# nrf7140_application register map
Vendor: Nordic Semiconductor; Series: nRF71; File version: 1
CPU: CM33 r0p4, little endian, MPU, FPU, 3 interrupt priority bits, 480 interrupts, 8 SAU regions
Registers are 32-bit, read-write, reset 0x0 unless marked. A register's access mark holds for its fields unless they carry their own. Offsets are from the block's base; [hi:lo] are bit positions; lines under a group give offsets from that group; {n}, {i} and the like mark numbered series; 'fields as' and 'values as' point back to an identical list.

## GLOBAL_GSI_NS (part 2 of 3) — GSI
Base 0x49008000
0x1000 DSI group — Unspecified
  0x00 VERSION reset 0x30313531 — Contains the version of the DSI host controller.
    [31:0] VERSION ro — This field indicates the version of the DSI.
  0x04 PWRUP — Controls the power up of the controller.
    [0] SHUTDOWNZ — This bit configures the controller either to power up or to reset.
      0=RESET (Reset the controller); 1=POWERUP (Power up the controller)
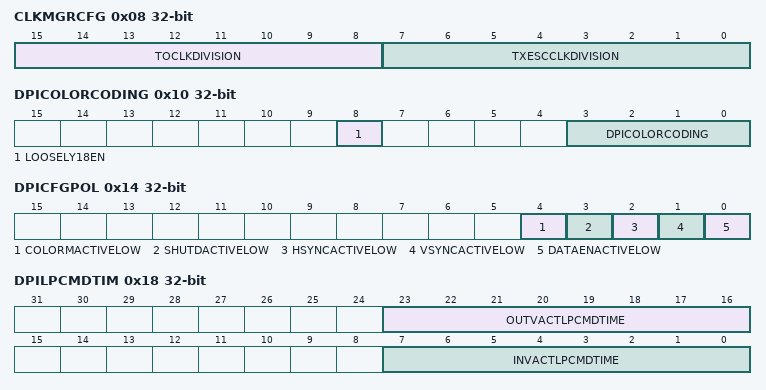
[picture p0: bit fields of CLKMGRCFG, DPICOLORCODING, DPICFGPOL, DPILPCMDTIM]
  0x08 CLKMGRCFG — Configures the factor for internal dividers to divide lanebyteclk for timeout purposes.
    [15:8] TOCLKDIVISION — This field indicates the division factor for the Time Out clock used as the timing unit in the configuration of high-speed to low-power and low-power to high-speed transition error.
    [7:0] TXESCCLKDIVISION — This field indicates the division factor for the TX Escape clock source (lanebyteclk). The values 0 and 1 stop the TX_ESC clock generation.
  0x0C DPIVCID — Configures the Virtual Channel ID for DPI traffic.
    [1:0] DPIVCID — This field configures the DPI virtual channel id that is indexed to the Video mode packets.
  0x10 DPICOLORCODING — Configures DPI color coding.
    [8] LOOSELY18EN — When set to 1, this bit activates loosely packed variant to 18-bit configurations.
    [3:0] DPICOLORCODING — This field configures the DPI color for Video Mode/eDPI Command Mode coding as follows:
      0=CC00 (16-bit configuration 1); 1=CC01 (16-bit configuration 2); 2=CC02 (16-bit configuration 3); 3=CC03 (18-bit configuration 1); 4=CC04 (18-bit configuration 2); 5=CC05 (24-bit); 6=CC06 (20-bit YCbCr 4:2:2 loosely packed / Reserved for eDPI Command Mode); 7=CC07 (24-bit YCbCr 4:2:2 / Reserved for eDPI Command Mode); 8=CC08 (16-bit YCbCr 4:2:2 / Reserved for eDPI Command Mode); 9=CC09 (30-bit - DSC_ENC 10bit / Reserved for eDPI Command Mode); 10=CC10 (36-bit / Reserved for eDPI Command Mode); 11=CC11 (12-bit YCbCr 4:2:0 / Reserved for eDPI Command Mode); 12=CC12 (DSC24 compressed Data); 13=CC13 (Unspecified); 14=CC14 (Unspecified); 15=CC15 (Unspecified)
  0x14 DPICFGPOL — Configures the polarity of DPI signals.
    [4] COLORMACTIVELOW — When set to 1, this bit configures the color mode pin (dpicolorm) as active low.
    [3] SHUTDACTIVELOW — When set to 1, this bit configures the shutdown pin (dpishutdn) as active low.
    [2] HSYNCACTIVELOW — When set to 1, this bit configures the horizontal synchronism pin (dpihsync) as active low.
    [1] VSYNCACTIVELOW — When set to 1, this bit configures the vertical synchronism pin (dpivsync) as active low.
    [0] DATAENACTIVELOW — When set to 1, this bit configures the data enable pin (dpidataen) as active low.
  0x18 DPILPCMDTIM — Configures the timing for low-power commands sent while in video mode.
    [23:16] OUTVACTLPCMDTIME — This field is used for the transmission of commands in low-power mode. It defines the size, in bytes, of the largest packet that can fit in a line during the VSA, VBP, and VFP regions.
    [7:0] INVACTLPCMDTIME — This field is used for the transmission of commands in low-power mode. It defines the size, in bytes, of the largest packet that can fit in a line during the VACT region.
  0x1C DBIVCID — Configures Virtual Channel ID for DBI traffic.
    [1:0] DBIVCID — This field configures the virtual channel id that is indexed to the DCS packets from DBI.
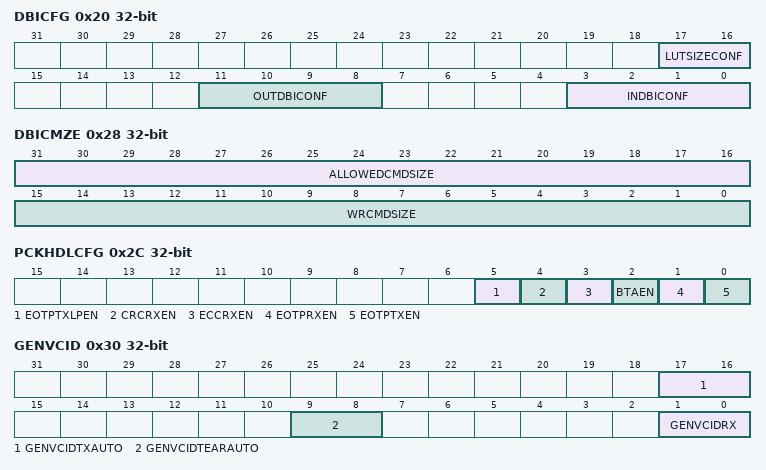
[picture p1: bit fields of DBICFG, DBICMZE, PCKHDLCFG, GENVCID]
  0x20 DBICFG — Configures the bit width of pixels for DBI.
    [17:16] LUTSIZECONF — This field configures the size used to transport the Write Lut commands as follows:
      0=LUTSIZE0 (16-bit color display); 1=LUTSIZE1 (18-bit color display); 2=LUTSIZE2 (24-bit color display); 3=LUTSIZE3 (32-bit color display)
    [11:8] OUTDBICONF — This field configures the DBI output pixel data as follows:
      0=PIXELDATA0 (8-bit 8 bpp); 1=PIXELDATA1 (8-bit 12 bpp); 2=PIXELDATA2 (8-bit 16 bpp); 3=PIXELDATA3 (8-bit 18 bpp); 4=PIXELDATA4 (8-bit 24 bpp); 5=PIXELDATA5 (9-bit 18 bpp); 6=PIXELDATA6 (16-bit 8 bpp); 7=PIXELDATA7 (16-bit 12 bpp); 8=PIXELDATA8 (16-bit 16 bpp); 9=PIXELDATA9 (16-bit 18 bpp, option 1); 10=PIXELDATA10 (16-bit 18 bpp, option 2); 11=PIXELDATA11 (16-bit 24 bpp, option 1); 12=PIXELDATA12 (16-bit 24 bpp, option 2)
    [3:0] INDBICONF — This field configures the DBI input pixel data as follows:
      values as OUTDBICONF
  0x24 DBIPARTITIONINGEN — Configures whether DSI is to partition DBI traffic automatically.
    [0] PARTITIONINGEN — When set to 1, this bit enables the use of write_memory_continue input commands (system needs to ensure correct partitioning of Long Write commands). When not set, partitioning is automatically performed in the DSI.
  0x28 DBICMZE — Configures the command size and the size for automatic partitioning of DBI packets.
    [31:16] ALLOWEDCMDSIZE — This field configures the maximum allowed size for a DCS write memory command. This field is used to partition a write memory command into one write_memory_start and a variable number of write_memory_continue commands. It is only used if the partitioning_en bit of the DBI_CFG register is disabled. The size of the DSI packet payload is the actual payload size minus 1, because the DCS command is in the DSI packet payload.
    [15:0] WRCMDSIZE — This field configures the size of the DCS write memory commands. The size of DSI packet payload is the actual payload size minus 1, because the DCS command is in the DSI packet payload.
  0x2C PCKHDLCFG — Configures how EoTp, BTA, CRC and ECC are to be used, to meet peripherals characteristics
    [5] EOTPTXLPEN — When set to 1, this bit enables the EoTp transmission in low-power.
    [4] CRCRXEN — When set to 1, this bit enables the CRC reception and error reporting.
    [3] ECCRXEN — When set to 1, this bit enables the ECC reception, error correction, and reporting.
    [2] BTAEN — When set to 1, this bit enables the Bus Turn-Around (BTA) request.
    [1] EOTPRXEN — When set to 1, this bit enables the EoTp reception.
    [0] EOTPTXEN — When set to 1, this bit enables the EoTp transmission in high-speed.
  0x30 GENVCID — Configures the Virtual Channel ID of READ responses to store and return to Generic interface.
    [17:16] GENVCIDTXAUTO — This field indicates the Generic interface virtual channel identification where generic packet is automatically generated & transmitted.
    [9:8] GENVCIDTEARAUTO — This field indicates the virtual channel identification for tear effect by hardware
    [1:0] GENVCIDRX — This field indicates the Generic interface read-back virtual channel identification.
  0x34 MODECFG reset 0x1 — Configures the mode of operation between Video or Command Mode. (Commands can still be sent while in video mode.)
    [0] CMDVIDEOMODE — This bit configures the operation mode:
      0=VIDMODE (video mode); 1=CMDMODE (command mode)
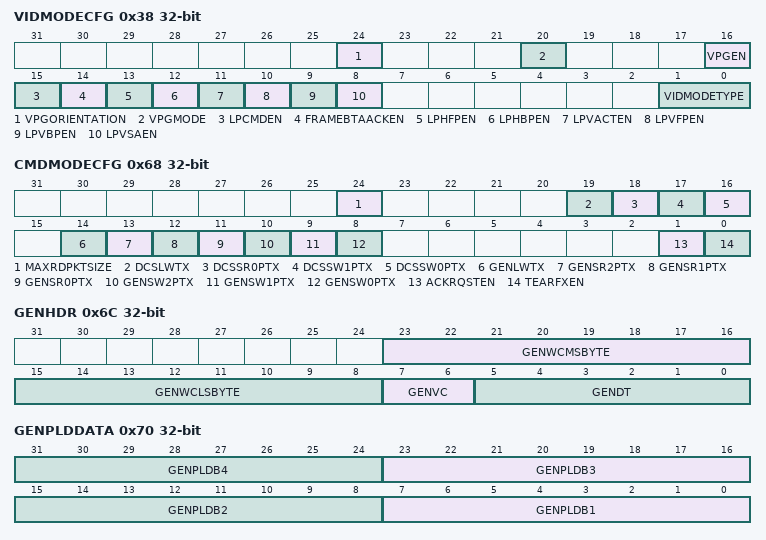
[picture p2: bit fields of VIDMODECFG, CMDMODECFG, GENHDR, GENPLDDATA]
  0x38 VIDMODECFG — Configures several aspects of Video mode operation, the transmission mode, switching to low-power in the middle of a frame, enabling acknowledge and whether to send commands in low-power.
    [24] VPGORIENTATION — This field indicates the color bar orientation as follows:
      0=VPGORENT0 (Vertical mode); 1=VPGORENT1 (Horizontal mode)
    [20] VPGMODE — This field is to select the pattern:
      0=COLORBAR (horizontal or vertical); 1=BERPATTERN (vertical only)
    [16] VPGEN — When set to 1, this bit enables the video mode pattern generator.
    [15] LPCMDEN — When set to 1, this bit enables the command transmission only in low-power mode.
    [14] FRAMEBTAACKEN — When set to 1, this bit enables the request for an acknowledge response at the end of a frame.
    [13] LPHFPEN — When set to 1, this bit enables the return to low-power inside the HFP period when timing allows.
    [12] LPHBPEN — When set to 1, this bit enables the return to low-power inside the HBP period when timing allows.
    [11] LPVACTEN — When set to 1, this bit enables the return to low-power inside the VACT period when timing allows.
    [10] LPVFPEN — When set to 1, this bit enables the return to low-power inside the VFP period when timing allows.
    [9] LPVBPEN — When set to 1, this bit enables the return to low-power inside the VBP period when timing allows.
    [8] LPVSAEN — When set to 1, this bit enables the return to low-power inside the VSA period when timing allows.
    [1:0] VIDMODETYPE — This field indicates the video mode transmission type as follows:
      0=VIDMODE0 (Non-burst with sync pulses); 1=VIDMODE1 (Non-burst with sync events); 2=VIDMODE2 (Burst mode); 3=VIDMODE3 (Burst mode)
  0x3C VIDPKTSIZE — Configures the video packet size.
    [13:0] VIDPKTSIZE — This field configures the number of pixels in a single video packet.
  0x40 VIDNUMCHUNKS — Configures the number of chunks to use. The data in each chunk has the size provided by VID_PKT_SIZE.
    [12:0] VIDNUMCHUNKS — This register configures the number of chunks to be transmitted during a Line period (a chunk is pair made of a video packet and a null packet). If set to 0 or 1, video line is still transmitted in a single packet. If set to 1 that packet is part of a chunk, meaning that a null packet follows it (if vid_null_size>0). Otherwise, multiple chunks are used to transmit each video line.
  0x44 VIDNULLSIZE — Configures the size of null packets.
    [12:0] VIDNULLSIZE — This register configures the number of bytes inside a null packet. Setting to 0 disables null packets.
  0x48 VIDHSATIME — Configures the video HSA time.
    [11:0] VIDHSATIME — This field configures the Horizontal Synchronism Active period in lane byte clock cycles.
  0x4C VIDHBPTIME — Configures the video HBP time.
    [11:0] VIDHBPTIME — This field configures the Horizontal Back Porch period in lane byte clock cycles.
  0x50 VIDHLINETIME — Configures the overall time for each video line.
    [14:0] VIDHLINETIME — This field configures the size of the total line time (HSA+HBP+HACT+HFP) counted in lane byte clock cycles.
  0x54 VIDVSALINES — Configures the VSA period.
    [9:0] VSALINES — This field configures the Vertical Synchronism Active period measured in number of horizontal lines.
  0x58 VIDVBPLINES — Configures the VBP period.
    [9:0] VBPLINES — This field configures the Vertical Back Porch period measured in number of horizontal lines.
  0x5C VIDVFPLINES — Configures the VFP period.
    [9:0] VFPLINES — This field configures the Vertical Front Porch period measured in number of horizontal lines.
  0x60 VIDVACTIVELINES — Configures the vertical resolution of video.
    [13:0] VACTIVELINES — This field configures the Vertical Active period measured in number of horizontal lines.
  0x68 CMDMODECFG — Configures several aspect of command mode operation, tearing effect, acknowledge for each packet and the speed mode to transmit each Data Type related to commands.
    [24] MAXRDPKTSIZE — This bit configures the maximum read packet size command transmission type:
      0=HIGHSPEED (Transition type is high-speed); 1=LOWPOWER (Transition type is low-power)
    [19] DCSLWTX — This bit configures the DCS long write packet command transmission type:
      values as MAXRDPKTSIZE
    [18] DCSSR0PTX — This bit configures the DCS short read packet with zero parameter command transmission type:
      values as MAXRDPKTSIZE
    [17] DCSSW1PTX — This bit configures the DCS short write packet with one parameter command transmission type:
      values as MAXRDPKTSIZE
    [16] DCSSW0PTX — This bit configures the DCS short write packet with zero parameter command transmission type:
      values as MAXRDPKTSIZE
    [14] GENLWTX — This bit configures the Generic long write packet command transmission type:
      values as MAXRDPKTSIZE
    [13] GENSR2PTX — This bit configures the Generic short read packet with two parameters command transmission type:
      values as MAXRDPKTSIZE
    [12] GENSR1PTX — This bit configures the Generic short read packet with one parameter command transmission type:
      values as MAXRDPKTSIZE
    [11] GENSR0PTX — This bit configures the Generic short read packet with zero parameter command transmission type:
      values as MAXRDPKTSIZE
    [10] GENSW2PTX — This bit configures the Generic short write packet with two parameters command transmission type:
      values as MAXRDPKTSIZE
    [9] GENSW1PTX — This bit configures the Generic short write packet with one parameter command transmission type:
      values as MAXRDPKTSIZE
    [8] GENSW0PTX — This bit configures the Generic short write packet with zero parameter command transmission type:
      values as MAXRDPKTSIZE
    [1] ACKRQSTEN — When set to 1, this bit enables the acknowledge request after each packet transmission.
    [0] TEARFXEN — When set to 1, this bit enables the tearing effect acknowledge request.
  0x6C GENHDR — Sets the header for new packets sent using the Generic interface.
    [23:16] GENWCMSBYTE — This field configures the most significant byte of the header packet's word count for long packets or data 1 for short packets.
    [15:8] GENWCLSBYTE — This field configures the least significant byte of the header packet's Word count for long packets or data 0 for short packets.
    [7:6] GENVC — This field configures the Virtual Channel ID of the header packet.
    [5:0] GENDT — This field configures the packet Data Type of the header packet.
  0x70 GENPLDDATA — Sets the payload for packets sent using the Generic interface and, when read returns the contents of READ responses from the peripheral.
    [8n-1:8n-8] GENPLDB{n} (n=1..4) — This field indicates byte {n} of the packet payload.
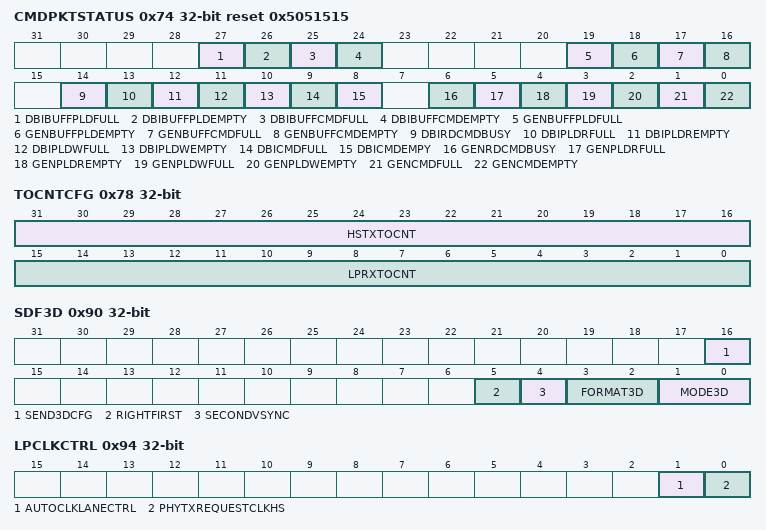
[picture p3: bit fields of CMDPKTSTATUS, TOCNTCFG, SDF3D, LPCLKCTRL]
  0x74 CMDPKTSTATUS reset 0x5051515 — Contains information about the status of FIFOs related to DBI and Generic interface.
    [27] DBIBUFFPLDFULL ro — This bit indicates the full status of the DBI payload internal buffer.
    [26] DBIBUFFPLDEMPTY ro — This bit indicates the empty status of the DBI payload internal buffer.
    [25] DBIBUFFCMDFULL ro — This bit indicates the full status of the DBI command internal buffer.
    [24] DBIBUFFCMDEMPTY ro — This bit indicates the empty status of the DBI command internal buffer.
    [19] GENBUFFPLDFULL ro — This bit indicates the full status of the generic payload internal buffer.
    [18] GENBUFFPLDEMPTY ro — This bit indicates the empty status of the generic payload internal buffer.
    [17] GENBUFFCMDFULL ro — This bit indicates the full status of the generic command internal buffer.
    [16] GENBUFFCMDEMPTY ro — This bit indicates the empty status of the generic command internal buffer.
    [14] DBIRDCMDBUSY ro — This bit is set when a read command is issued and cleared when the entire response is stored in the FIFO for DBI interface.
    [13] DBIPLDRFULL ro — This bit indicates the full status of the DBI read payload FIFO.
    [12] DBIPLDREMPTY ro — This bit indicates the empty status of the DBI read payload
    [11] DBIPLDWFULL ro — This bit indicates the full status of the DBI write payload FIFO.
    [10] DBIPLDWEMPTY ro — This bit indicates the empty status of the DBI write payload FIFO.
    [9] DBICMDFULL ro — This bit indicates the full status of the DBI command FIFO.
    [8] DBICMDEMPY ro — This bit indicates the empty status of the DBI command FIFO.
    [6] GENRDCMDBUSY ro — This bit is set when a read command is issued and cleared when the entire response is stored in the FIFO for GENERIC interface.
    [5] GENPLDRFULL ro — This bit indicates the full status of the generic read payload FIFO.
    [4] GENPLDREMPTY ro — This bit indicates the empty status of the generic read payload FIFO.
    [3] GENPLDWFULL ro — This bit indicates the full status of the generic write payload FIFO.
    [2] GENPLDWEMPTY ro — This bit indicates the empty status of the generic write payload FIFO.
    [1] GENCMDFULL ro — This bit indicates the full status of the generic command FIFO.
    [0] GENCMDEMPTY ro — This bit indicates the empty status of the generic command FIFO.
  0x78 TOCNTCFG — Configures counters that trigger timeout errors. These are used to warn the system of a failure, through an interrupt, and restart the controller in case of unexpected situations that cause deadlock conditions.
    [31:16] HSTXTOCNT — This field configures the timeout counter that triggers a high-speed transmission timeout contention detection (measured in TO_CLK_DIVISION cycles).
    [15:0] LPRXTOCNT — This field configures the timeout counter that triggers a low-power reception timeout contention detection (measured in TO_CLK_DIVISION cycles).
  0x7C HSRDTOCNT — Configures the Peripheral Response timeout after high-speed Read operations.
    [15:0] HSRDTOCNT — This field sets a period for which DSI keeps the link still, after sending a high-speed Read operation. This period is measured in cycles of lanebyteclk, starts to count when the D-PHY enters stop state and causes no interrupts.
  0x80 LPRDTOCNT — Configures the Peripheral Response timeout after low-power Read operations.
    [15:0] LPRDTOCNT — This field sets a period for which DSI keeps the link still, after sending a low-power Read operation. This period is measured in cycles of lanebyteclk, starts to count when the D-PHY enters stop state and causes no interrupts.
  0x84 HSWRTOCNT — Configures the Peripheral Response timeout after high-speed Write operations.
    [15:0] HSWRTOCNT — This field sets a period for which DSI keeps the link still, after sending a high-speed Write operation. This period is measured in cycles of lanebyteclk, starts to count when the D-PHY enters stop state and causes no interrupts.
  0x88 LPWRTOCNT — Configures the Peripheral Response timeout after low-power Write operations.
    [15:0] LPWRTOCNT — This field sets a period for which DSI keeps the link still, after sending a low-power Write operation. This period is measured in cycles of lanebyteclk, starts to count when the D-PHY enters stop state and causes no interrupts.
  0x8C BTATOCNT — Configures the Peripheral Response timeout after Bus Turnaround completion.
    [15:0] BTATOCNT — This field sets a period for which DSI keeps the link still, after completing a Bus Turnaround. This period is measured in cycles of lanebyteclk, starts to count when the D-PHY enters stop state and causes no interrupts.
  0x90 SDF3D — Stores 3D control information for VSS packets in video mode.
    [16] SEND3DCFG — When set, causes the next VSS packet to include 3D control payload in every VSS packet.
    [5] RIGHTFIRST — This bit defines the left/right order:
      0=LFIRST (left eye is sent first, then right eye); 1=RFIRST (right eye data is sent first, then left eye)
    [4] SECONDVSYNC — This field defines whether there is a second VSYNC pulse between Left and Right Images, when 3D Image Format is Frame-based:
      0=NOSYNC (No sync pulses between left and right data); 1=SYNC (Sync pulse HSYNC, VSYNC, blanking between left and right data)
    [3:2] FORMAT3D — This field defines 3D Image Format:
      0=LINE (Alternating lines of left and right data); 1=FRAME (Alternating frames of left and right data); 2=PIXEL (Alternating pixels of left and right data)
    [1:0] MODE3D — This field defines 3D Mode On/Off and Display Orientation:
      0=MODE0 (3D Mode Off , 2D Mode On); 1=MODE1 (3D Mode On, Portrait Orientation); 2=MODE2 (3D Mode On, Landscape Orientation); 3=MODE3 (Reserved, not used)
  0x94 LPCLKCTRL — Configures the possibility for using non continuous clock in the clock lane.
    [1] AUTOCLKLANECTRL — This bit enables the automatic mechanism to stop providing clock in the clock lane when time allows.
    [0] PHYTXREQUESTCLKHS — This bit controls the D-PHY PPI txrequestclkhs signal.
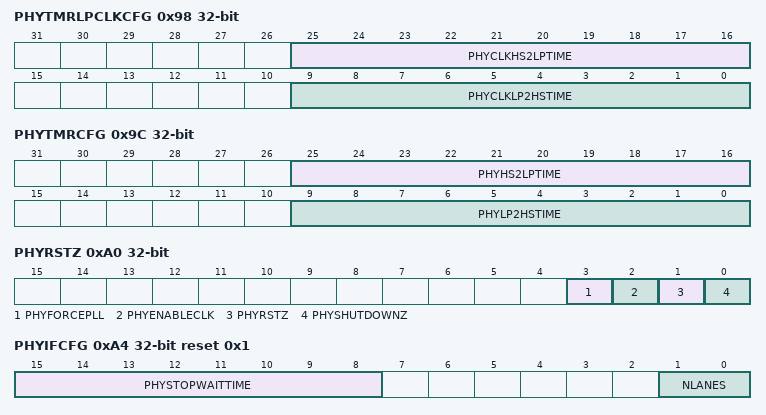
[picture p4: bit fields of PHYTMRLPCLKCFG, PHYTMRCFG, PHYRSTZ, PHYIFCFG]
  0x98 PHYTMRLPCLKCFG — Sets the time that DSI assumes in calculations for the clock lane to switch between high-speed and low-power.
    [25:16] PHYCLKHS2LPTIME — This field configures the maximum time that the D-PHY clock lane takes to go from high-speed to low-power transmission measured in lane byte clock cycles.
    [9:0] PHYCLKLP2HSTIME — This field configures the maximum time that the D-PHY clock lane takes to go from low-power to high-speed transmission measured in lane byte clock cycles.
  0x9C PHYTMRCFG — Sets the time that DSI assumes in calculations for the data lanes to switch between high-speed and low-power.
    [25:16] PHYHS2LPTIME — This field configures the maximum time that the D-PHY data lanes take to go from high-speed to low-power transmission measured in lane byte clock cycles.
    [9:0] PHYLP2HSTIME — This field configures the maximum time that the D-PHY data lanes take to go from low-power to high-speed transmission measured in lane byte clock cycles.
  0xA0 PHYRSTZ — Controls resets and the PLL of the D-PHY.
    [3] PHYFORCEPLL — When the D-PHY is in ULPS, this bit enables the D-PHY PLL.
    [2] PHYENABLECLK — When set to 1, this bit enables the D-PHY Clock Lane Module.
    [1] PHYRSTZ — When set to 0, this bit places the digital section of the D-PHY in the reset state.
    [0] PHYSHUTDOWNZ — When set to 0, this bit places the complete D-PHY macro in power-down state.
  0xA4 PHYIFCFG reset 0x1 — Configures the number of active lanes and the minimum time to remain in stop state.
    [15:8] PHYSTOPWAITTIME — This field configures the minimum time PHY needs to stay in StopState before requesting an high-speed transmission
    [1:0] NLANES — This field configures the number of active data lanes:
      0=ONELANES (lane 0); 1=TWOLANES (lanes 0 and 1); 2=THREELANES (lanes 0, 1, and 2); 3=FOURLANES (lanes 0, 1, 2, and 3)
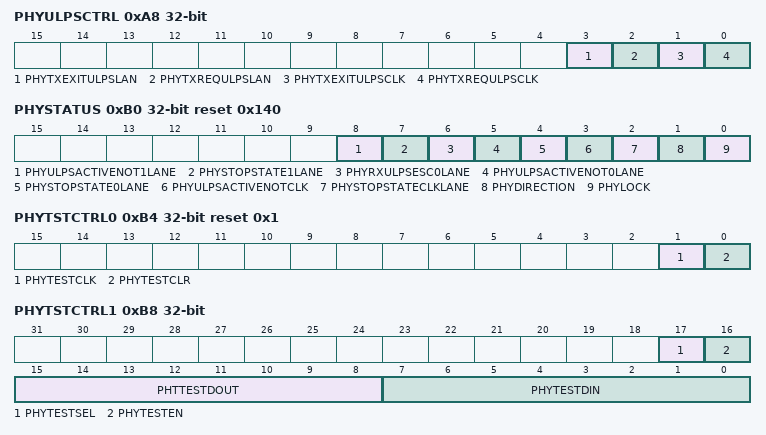
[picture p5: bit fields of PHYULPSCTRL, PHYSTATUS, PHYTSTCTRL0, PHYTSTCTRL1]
  0xA8 PHYULPSCTRL — Configures entering and leaving ULPS in the D-PHY.
    [3] PHYTXEXITULPSLAN — ULPS mode Exit on all active data lanes.
    [2] PHYTXREQULPSLAN — ULPS mode Request on all active data lanes.
    [1] PHYTXEXITULPSCLK — ULPS mode Exit on clock lane.
    [0] PHYTXREQULPSCLK — ULPS mode Request on clock lane.
  0xAC PHYTXTRIGGERS — Configures the pins that activate triggers in the D-PHY.
    [3:0] PHYTXTRIGGERS — This field controls the trigger transmissions.
  0xB0 PHYSTATUS reset 0x140 — Contains information about the status of the D-PHY.
    [8] PHYULPSACTIVENOT1LANE ro — This bit indicates the status of ulpsactivenot1lane D-PHY signal.
    [7] PHYSTOPSTATE1LANE ro — This bit indicates the status of phystopstate1lane D-PHY signal.
    [6] PHYRXULPSESC0LANE ro — This bit indicates the status of rxulpsesc0lane D-PHY signal.
    [5] PHYULPSACTIVENOT0LANE ro — This bit indicates the status of ulpsactivenot0lane D-PHY signal.
    [4] PHYSTOPSTATE0LANE ro — This bit indicates the status of phystopstate0lane D-PHY signal.
    [3] PHYULPSACTIVENOTCLK ro — This bit indicates the status of phyulpsactivenotclk D-PHY signal.
    [2] PHYSTOPSTATECLKLANE ro — This bit indicates the status of phystopstateclklane D-PHY signal.
    [1] PHYDIRECTION ro — This bit indicates the status of phydirection D-PHY signal.
    [0] PHYLOCK ro — This bit indicates the status of phylock D-PHY signal.
  0xB4 PHYTSTCTRL0 reset 0x1 — Controls clock and clear pins of the D-PHY vendor specific interface.
    [1] PHYTESTCLK — This bit is used to clock the TESTDIN bus into the D-PHY.
    [0] PHYTESTCLR — PHY test interface clear (active high).
  0xB8 PHYTSTCTRL1 — Controls data and enable pins of the D-PHY vendor specific interface.
    [17] PHYTESTSEL — PHY BiDIR MUX selector
    [16] PHYTESTEN — PHY test interface operation selector:
      0=WRITEDATA (the data write operation is set on the rising edge of the testclk signal.); 1=WRITEADDR (the address write operation is set on the falling edge of the testclk signal.)
    [15:8] PHTTESTDOUT ro — PHY output 8-bit data bus for read-back and internal probing functionalities.
    [7:0] PHYTESTDIN — PHY test interface input 8-bit data bus for internal register programming and test functionalities access.
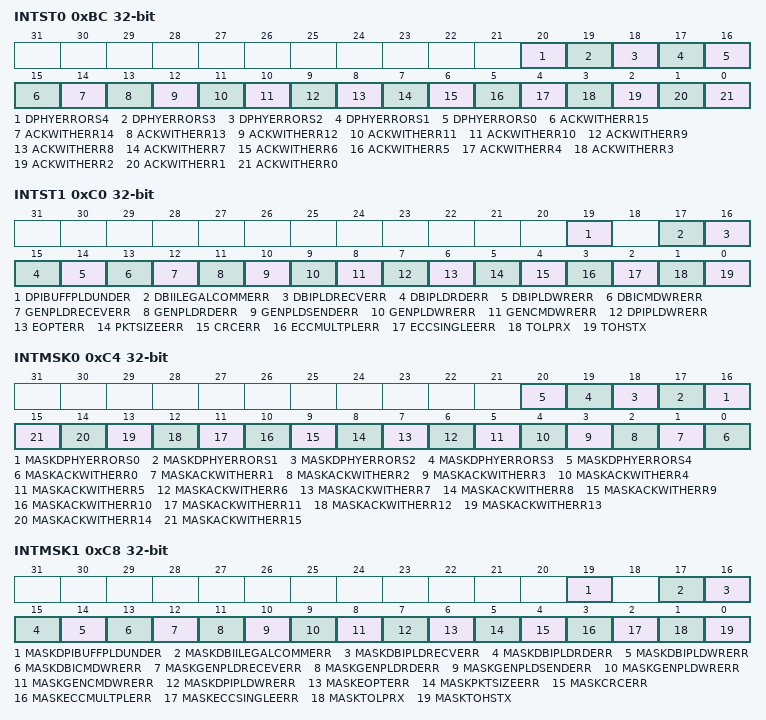
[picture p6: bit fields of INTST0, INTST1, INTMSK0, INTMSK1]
  0xBC INTST0 — Contains the status of interrupt sources from acknowledge reports and the D-PHY.
    [20] DPHYERRORS4 ro — This bit indicates LP1 contention error ErrContentionLP1 from Lane 0.
    [19] DPHYERRORS3 ro — This bit indicates LP0 contention error ErrContentionLP0 from Lane 0.
    [18] DPHYERRORS2 ro — This bit indicates control error ErrControl from Lane 0.
    [17] DPHYERRORS1 ro — This bit indicates ErrSyncEsc low-power data transmission synchronization error from Lane 0.
    [16] DPHYERRORS0 ro — This bit indicates ErrEsc escape entry error from Lane 0.
    [15] ACKWITHERR15 ro — This bit retrieves the DSI protocol violation from the Acknowledge error report.
    [14] ACKWITHERR14 ro — This bit retrieves the reserved (specific to device) from the Acknowledge error report.
    [13] ACKWITHERR13 ro — This bit retrieves the invalid transmission length from the Acknowledge error report.
    [12] ACKWITHERR12 ro — This bit retrieves the DSI VC ID Invalid from the Acknowledge error report.
    [11] ACKWITHERR11 ro — This bit retrieves the not recognized DSI data type from the Acknowledge error report.
    [10] ACKWITHERR10 ro — This bit retrieves the checksum error (long packet only) from the Acknowledge error report.
    [9] ACKWITHERR9 ro — This bit retrieves the ECC error, multi-bit (detected, not corrected) from the Acknowledge error report.
    [8] ACKWITHERR8 ro — This bit retrieves the ECC error, single-bit (detected and corrected) from the Acknowledge error report.
    [7] ACKWITHERR7 ro — This bit retrieves the Contention Detected error from the Acknownledge error report.
    [6] ACKWITHERR6 ro — This bit retrieves the False Control error from the Acknowledge error report.
    [5] ACKWITHERR5 ro — This bit retrieves the Peripheral Timeout error from the Acknowledge error report.
    [4] ACKWITHERR4 ro — This bit retrieves the low-power Transmit Sync error from the Acknowledge error report.
    [3] ACKWITHERR3 ro — This bit retrieves the Escape Mode Entry Command error from the Acknowledge error report.
    [2] ACKWITHERR2 ro — This bit retrieves the EoT Sync error from the Acknowledge error report.
    [1] ACKWITHERR1 ro — This bit retrieves the SoT Sync error from the Acknowledge error report.
    [0] ACKWITHERR0 ro — This bit retrieves the SoT error from the Acknowledge error report.
  0xC0 INTST1 — Contains the status of interrupt sources related to timeouts, ECC, CRC, packet size, EoTp, Generic and DBI interfaces.
    [19] DPIBUFFPLDUNDER ro — This bit indicates that an underflow has occurred when reading payload to build DSI packet for video mode
    [17] DBIILEGALCOMMERR ro — This bit indicates that an attempt to write an illegal command on the DBI interface is made and the controller is blocked by transmission.
    [16] DBIPLDRECVERR ro — This bit indicates that during a DBI read back packet, the payload FIFO becomes full and the received data is corrupted.
    [15] DBIPLDRDERR ro — This bit indicates that during a DCS read data, the payload FIFO goes empty and the data sent to the interface is corrupted.
    [14] DBIPLDWRERR ro — This bit indicates that the system tried to write the payload data through the DBI interface and the FIFO is full. Therefore, the command is not written.
    [13] DBICMDWRERR ro — This bit indicates that the system tried to write a command through the DBI but the command FIFO is full. Therefore, the command is not written.
    [12] GENPLDRECEVERR ro — This bit indicates that during a generic interface packet read back, the payload FIFO becomes full and the received data is corrupted.
    [11] GENPLDRDERR ro — This bit indicates that during a DCS read data, the payload FIFO becomes empty and the data sent to the interface is corrupted.
    [10] GENPLDSENDERR ro — This bit indicates that during a Generic interface packet build, the payload FIFO becomes empty and corrupt data is sent.
    [9] GENPLDWRERR ro — This bit indicates that the system tried to write a payload data through the Generic interface and the FIFO is full. Therefore, the payload is not written.
    [8] GENCMDWRERR ro — This bit indicates that the system tried to write a command through the Generic interface and the FIFO is full. Therefore, the command is not written.
    [7] DPIPLDWRERR ro — This bit indicates that during a DPI pixel line storage, the payload FIFO becomes full and the data stored is corrupted.
    [6] EOPTERR ro — This bit indicates that the EoTp packet has not been received at the end of the incoming peripheral transmission.
    [5] PKTSIZEERR ro — This bit indicates that the packet size error has been detected during the packet reception.
    [4] CRCERR ro — This bit indicates that the CRC error has been detected in the received packet payload.
    [3] ECCMULTPLERR ro — This bit indicates that the ECC multiple error has been detected in a received packet.
    [2] ECCSINGLEERR ro — This bit indicates that the ECC single error has been detected and corrected in a received packet.
    [1] TOLPRX ro — This bit indicates that the low-power reception timeout counter reached the end and contention has been detected.
    [0] TOHSTX ro — This bit indicates that the high-speed transmission timeout counter reached the end and contention has been detected.
  0xC4 INTMSK0 — Configures masks for the sources of interrupts that affect the INT_ST0 register. Write 1 to un-mask each error report.
    [n+16] MASKDPHYERRORS{n} (n=0..4) — Mask for dphy_errors_{n}
    [n] MASKACKWITHERR{n} (n=0..15) — Mask for ack_with_err_{n}
  0xC8 INTMSK1 — Configures masks for the sources of interrupts that affect the INT_ST1 register.
    [19] MASKDPIBUFFPLDUNDER — Mask for dpi_buff_pld_under
    [17] MASKDBIILEGALCOMMERR — Mask for dbi_ilegal_comm_err
    [16] MASKDBIPLDRECVERR — Mask for dbi_pld_recv_err
    [15] MASKDBIPLDRDERR — Mask for dbi_pld_rd_err
    [14] MASKDBIPLDWRERR — Mask for dbi_pld_wr_err
    [13] MASKDBICMDWRERR — Mask for dbi_cmd_wr_err
    [12] MASKGENPLDRECEVERR — Mask for gen_pld_recev_err
    [11] MASKGENPLDRDERR — Mask for gen_pld_rd_err
    [10] MASKGENPLDSENDERR — Mask for gen_pld_send_err
    [9] MASKGENPLDWRERR — Mask for gen_pld_wr_err
    [8] MASKGENCMDWRERR — Mask for gen_cmd_wr_err
    [7] MASKDPIPLDWRERR — Mask for dpi_pld_wr_err
    [6] MASKEOPTERR — Mask for eopt_err
    [5] MASKPKTSIZEERR — Mask for pkt_size_err
    [4] MASKCRCERR — Mask for crc_err
    [3] MASKECCMULTPLERR — Mask for ecc_multpl_err
    [2] MASKECCSINGLEERR — Mask for ecc_single_err
    [1] MASKTOLPRX — Mask for to_lp_rx
    [0] MASKTOHSTX — Mask for to_hs_tx
  0xCC PHYCAL — Controls the skew calibration of D-PHY.
    [0] TXSKEWCALHS — High-speed skew calibration is started when txskewcalhs is set high (assuming that PHY is in Stop state).
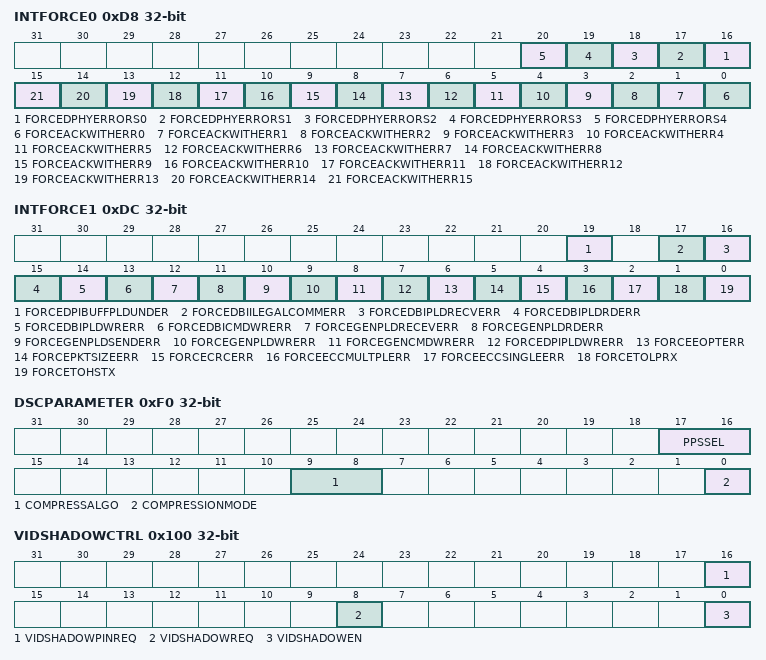
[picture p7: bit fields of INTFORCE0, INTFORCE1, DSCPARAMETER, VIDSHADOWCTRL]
  0xD8 INTFORCE0 — Forces interrupt that affect the INT_ST0 register.
    [n+16] FORCEDPHYERRORS{n} (n=0..4), [n] FORCEACKWITHERR{n} (n=0..15)
  0xDC INTFORCE1 — Forces interrupts that affect the INT_ST1 register.
    [19] FORCEDPIBUFFPLDUNDER — Force for dpi_buff_pld_under.
    [17] FORCEDBIILEGALCOMMERR
    [16] FORCEDBIPLDRECVERR
    [15] FORCEDBIPLDRDERR
    [14] FORCEDBIPLDWRERR
    [13] FORCEDBICMDWRERR
    [12] FORCEGENPLDRECEVERR
    [11] FORCEGENPLDRDERR
    [10] FORCEGENPLDSENDERR
    [9] FORCEGENPLDWRERR
    [8] FORCEGENCMDWRERR
    [7] FORCEDPIPLDWRERR
    [6] FORCEEOPTERR
    [5] FORCEPKTSIZEERR
    [4] FORCECRCERR
    [3] FORCEECCMULTPLERR
    [2] FORCEECCSINGLEERR
    [1] FORCETOLPRX
    [0] FORCETOHSTX
  0xF0 DSCPARAMETER — Configures Display Stream Compression.
    [17:16] PPSSEL — This field indicates the PPS selector:
      {v}=PPS Table {v+1} (v=0..3)
    [9:8] COMPRESSALGO — This field indicates the algorithm identifier:
      0=ALGO0 (VESA DSC Standard 1.1); 1=ALGO1 (reserved, not used); 2=ALGO2 (reserved, not used); 3=ALGO3 (vendor-specific algorithm)
    [0] COMPRESSIONMODE — When set to 1, this bit enables the compression mode.
  0xF4 PHYTMRRDCFG — Configures times related to PHY to perform some operations in lane byte clock cycles.
    [14:0] MAXRDTIME — This field configures the maximum time required to perform a read command in lane byte clock cycles. This register can only be modified when no read command is in progress.
  0x100 VIDSHADOWCTRL — Controls dpi shadow feature
    [16] VIDSHADOWPINREQ — When set to 1, the video request is done by external pin. In this mode vid_shadow_req is ignored.
    [8] VIDSHADOWREQ — When set to 1, this bit request that the dpi registers from regbank are copied to the auxiliary registers. When the request is completed this bit is auto clear.
    [0] VIDSHADOWEN — When set to 1, DPI receives the active configuration from the auxiliary registers. When the feature is set at the same time than vid_shadow_req the auxiliary registers are automatically updated.
  0x10C DPIVCIDACT — Holds the value that controller is using for DPI_VCID.
    [1:0] DPIVCID ro — This field specifies the DPI virtual channel id that is indexed to the Video mode packets.
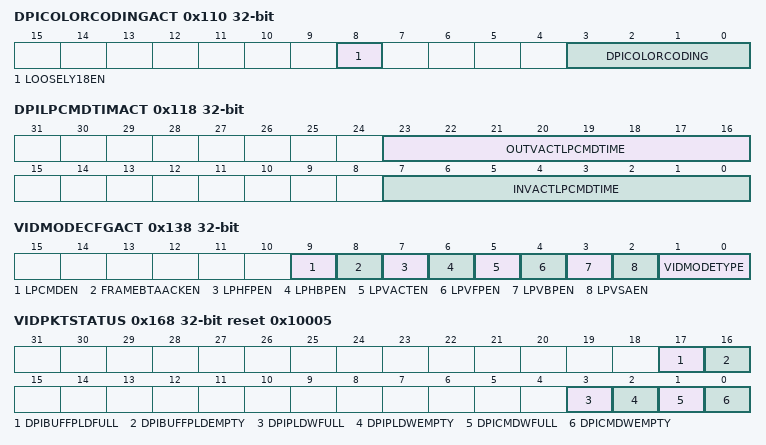
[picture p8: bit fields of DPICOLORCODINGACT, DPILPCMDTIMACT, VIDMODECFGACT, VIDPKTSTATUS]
  0x110 DPICOLORCODINGACT — Holds the value that controller is using for DPI_COLOR_CODING.
    [8] LOOSELY18EN ro — When 1, this bit activates loosely packed variant to 18-bit configurations.
    [3:0] DPICOLORCODING ro — This field configures the DPI color for Video Mode/eDPI Command Mode coding as follows:
      values as DSI.DPICOLORCODING.DPICOLORCODING
  0x118 DPILPCMDTIMACT — Holds the value that controller is using for DPI_LP_CMD_TIM.
    [23:16] OUTVACTLPCMDTIME ro — This field is used for the transmission of commands in low-power mode. It specifies the size, in bytes, of the largest packet that can fit in a line during the VSA, VBP, and VFP regions.
    [7:0] INVACTLPCMDTIME ro — This field is used for the transmission of commands in low-power mode. It specifies the size, in bytes, of the largest packet that can fit in a line during the VACT region.
  0x138 VIDMODECFGACT — Holds the value that controller is using for VID_MODE_CFG.
    [9] LPCMDEN ro — When 1, this bit enables the command transmission only in low-power mode.
    [8] FRAMEBTAACKEN ro — When 1, this bit enables the request for an acknowledge response at the end of a frame.
    [7] LPHFPEN ro — When 1, this bit enables the return to low-power inside the HFP period when timing allows.
    [6] LPHBPEN ro — When 1, this bit enables the return to low-power inside the HBP period when timing allows.
    [5] LPVACTEN ro — When 1, this bit enables the return to low-power inside the VACT period when timing allows.
    [4] LPVFPEN ro — When 1, this bit enables the return to low-power inside the VFP period when timing allows.
    [3] LPVBPEN ro — When 1, this bit enables the return to low-power inside the VBP period when timing allows.
    [2] LPVSAEN ro — When 1, this bit enables the return to low-power inside the VSA period when timing allows.
    [1:0] VIDMODETYPE ro — This field specifies the video mode transmission type as follows:
      values as DSI.VIDMODECFG.VIDMODETYPE
  0x13C VIDPKTSIZEACT — Holds the value that controller is using for VID_PKT_SIZE.
    [13:0] VIDPKTSIZE ro — This field specifies the number of pixels in a single video packet. For 18-bit not loosely packed this number must be a multiple of 4 and YCbCr Data Types, it must be a multiple of 2, as described in DSI specification.
  0x140 VIDNUMCHUNKSACT — This register holds the value that controller is using for VID_NUM_CHUNKS.
    [12:0] VIDNUMCHUNKS ro — This register specifies the number of chunks to be transmitted during a Line period (a chunk is pair made of a video packet and a null packet). If set to 0 or 1, video line is still transmitted in a single packet. If set to 1 that packet is part of a chunk, meaning that a null packet follows it (if vid_null_size>0). Otherwise, multiple chunks are used to transmit each video line.
  0x144 VIDNULLSIZEACT — Holds the value that controller is using for VID_NULL_SIZE.
    [12:0] VIDNULLSIZE ro — This register specifies the number of bytes inside a null packet. Setting to 0 disables null packets.
  0x148 VIDHSATIMEACT — Holds the value that controller is using for VID_HSA_TIME.
    [11:0] VIDHSATIME ro — This field specifies the Horizontal Synchronism Active period in lane byte clock cycles.
  0x14C VIDHBPTIMEACT — Holds the value that controller is using for VID_HBP_TIME.
    [11:0] VIDHBPTIME ro — This field specifies the Horizontal Back Porch period in lane byte clock cycles.
  0x150 VIDHLINETIMEACT — Holds the value that controller is using for VID_HLINE_TIME.
    [14:0] VIDHLINETIME ro — This field specifies the size of the total line time (HSA+HBP+HACT+HFP) counted in lane byte clock cycles.
  0x154 VIDVSALINESACT — Holds the value that controller is using for VID_VSA_LINES.
    [9:0] VSALINES ro — This field specifies the Vertical Synchronism Active period measured in number of horizontal lines.
  0x158 VIDVBPLINESACT — Holds the value that controller is using for VID_VBP_LINES.
    [9:0] VBPLINES ro — This field specifies the Vertical Back Porch period measured in number of horizontal lines.
  0x15C VIDVFPLINESACT — Holds the value that controller is using for VID_VFP_LINES.
    [9:0] VFPLINES ro — This field specifies the Vertical Front Porch period measured in number of horizontal lines.
  0x160 VIDVACTIVELINESACT — Holds the value that controller is using for VID_VACTIVE_LINES.
    [13:0] VACTIVELINES ro — This field specifies the Vertical Active period measured in number of horizontal lines.
  0x168 VIDPKTSTATUS reset 0x10005 — Contains information about the status of FIFOs related to DPI and eDPI interfaces.
    [17] DPIBUFFPLDFULL ro — This bit indicates the full status of the payload internal buffer for video Mode. This bit is set to 0 for command Mode.
    [16] DPIBUFFPLDEMPTY ro — This bit indicates the empty status of the payload internal buffer for video Mode. This bit is set to 0 for command Mode.
    [3] DPIPLDWFULL ro — This bit indicates the full status of write payload FIFO for video Mode. This bit is set to 0 for command Mode.
    [2] DPIPLDWEMPTY ro — This bit indicates the empty status of write payload FIFO for video Mode. This bit is set to 0 for command Mode.
    [1] DPICMDWFULL ro — This bit indicates the full status of write command FIFO for video Mode. This bit is set to 0 for command Mode.
    [0] DPICMDWEMPTY ro — This bit indicates the empty status of write command FIFO for video Mode. This bit is set to 0 for command Mode.
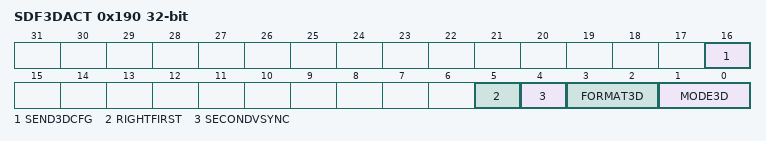
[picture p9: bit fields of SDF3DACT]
  0x190 SDF3DACT — Holds the value that controller is using for SDF_3D.
    [16] SEND3DCFG ro — When set, causes the next VSS packet to include 3D control payload in every VSS packet.
    [5] RIGHTFIRST ro — This bit specifies the left/right order:
      0=LEFTFIRST (left eye is sent first, then right eye); 1=RIGHTFIRST (right eye data is sent first, then left eye)
    [4] SECONDVSYNC ro — This field specifies whether there is a second VSYNC pulse between Left and Right Images, when 3D Image Format is Frame-based:
      0=NOSYNCPULSE (No sync pulses between left and right data.); 1=SYNCPULSE (Sync pulse (HSYNC, VSYNC, blanking) between left and right data.)
    [3:2] FORMAT3D ro — This field specifies 3D Image Format:
      values as DSI.SDF3D.FORMAT3D
    [1:0] MODE3D ro — This field specifies 3D Mode On/Off and Display Orientation:
      0=MODE0 (3D Mode Off, 2D Mode On); 1=MODE1 (3D Mode On, Portrait Orientation); 2=MODE2 (3D Mode On, Landscape Orientation); 3=MODE3 (Reserved, not used)
